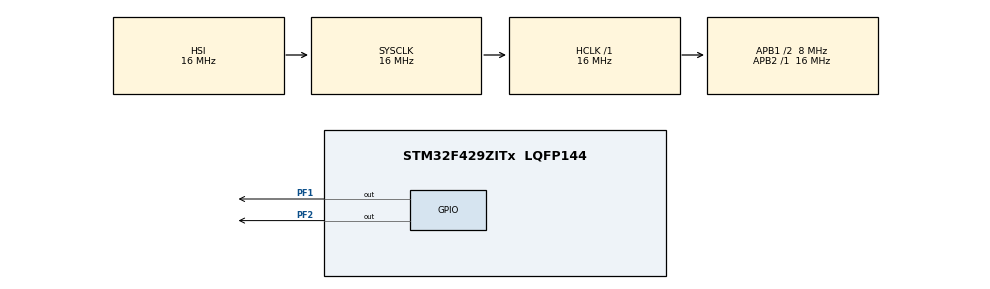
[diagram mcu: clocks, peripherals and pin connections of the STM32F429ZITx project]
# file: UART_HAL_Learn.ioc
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Mcu.Family=STM32F4
Mcu.Name=STM32F429ZITx
Mcu.Package=LQFP144
NVIC.PriorityGroup=NVIC_PRIORITYGROUP_4
PA13.Mode=Serial_Wire
PA13.Signal=SYS_JTMS-SWDIO
PA14.Mode=Serial_Wire
PA14.Signal=SYS_JTCK-SWCLK
PF1.Signal=GPIO_Output
PF2.Signal=GPIO_Output
ProjectManager.HeapSize=0x200
ProjectManager.StackSize=0x400
ProjectManager.TargetToolchain=STM32CubeIDE
RCC.48MHZClocksFreq_Value=96000000
RCC.AHBFreq_Value=16000000
RCC.APB1CLKDivider=RCC_HCLK_DIV2
RCC.APB1Freq_Value=8000000
RCC.APB1TimFreq_Value=16000000
RCC.APB2Freq_Value=16000000
RCC.APB2TimFreq_Value=16000000
RCC.CortexFreq_Value=16000000
RCC.HCLKFreq_Value=16000000
RCC.HSE_VALUE=8000000
RCC.HSI_VALUE=16000000
RCC.LSE_VALUE=32768
RCC.PLLM=4
RCC.PLLN=120
RCC.PLLQ=5
RCC.PLLSAIN=50
RCC.SYSCLKFreq_VALUE=16000000
RCC.VCOOutputFreq_Value=480000000
board=STM32F429I-DISC1

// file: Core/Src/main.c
/* USER CODE BEGIN Header */
/**
  ******************************************************************************
  * @file           : main.c
  * @brief          : Main program body
  ******************************************************************************
  * @attention
  *
  * Copyright (c) 2024 STMicroelectronics.
  * All rights reserved.
  *
  * This software is licensed under terms that can be found in the LICENSE file
  * in the root directory of this software component.
  * If no LICENSE file comes with this software, it is provided AS-IS.
  *
  ******************************************************************************
  */
/* USER CODE END Header */
#include "main.h"

void SystemClock_Config(void);
static void MX_GPIO_Init(void);

int main(void)
{

  /* MCU Configuration--------------------------------------------------------*/

  /* Reset of all peripherals, Initializes the Flash interface and the Systick. */
  HAL_Init();

  /* Configure the system clock */
  SystemClock_Config();

  /* Initialize all configured peripherals */
  MX_GPIO_Init();
  /* USER CODE BEGIN 2 */
  /** Enable clock access to GPIOA, USART1 */
  __HAL_RCC_USART1_CLK_ENABLE();
  /** Configure PA9, PA10 to Alternate function mode, value = 7 */
  GPIO_InitTypeDef GPIO_USART1;
  GPIO_USART1.Pin = GPIO_PIN_9 | GPIO_PIN_10;
  GPIO_USART1.Mode = GPIO_MODE_AF_PP;
  GPIO_USART1.Alternate = GPIO_AF7_USART1;
  HAL_GPIO_Init(GPIOA, &GPIO_USART1);
  /** Configure USART1 */
  UART_InitTypeDef UART1_Init;
  UART1_Init.OverSampling = UART_OVERSAMPLING_16;
  UART1_Init.Mode = UART_MODE_TX_RX;
  UART1_Init.WordLength = UART_WORDLENGTH_8B;
  UART1_Init.Parity = UART_PARITY_NONE;
  UART1_Init.StopBits = UART_STOPBITS_1;
  UART1_Init.BaudRate = 9600U;
  UART_HandleTypeDef hUART1;
  hUART1.Init = UART1_Init;
  hUART1.Instance = USART1;
  HAL_UART_Init(&hUART1);
//  __HAL_UART_ENABLE(&hUART1);

  /* USER CODE END 2 */

  /* Infinite loop */
  /* USER CODE BEGIN WHILE */
  unsigned char data = 0;
  const unsigned char carriage_return = '\r';
  const unsigned char line_feed = '\n';
  while (1)
  {
    /* USER CODE END WHILE */

    /* USER CODE BEGIN 3 */
	while(!__HAL_UART_GET_FLAG(&hUART1, UART_FLAG_RXNE)){}
	HAL_UART_Receive(&hUART1, &data, 1, 10000);
	while(!__HAL_UART_GET_FLAG(&hUART1,UART_FLAG_TXE)){}
	if(data != '\r')
		HAL_UART_Transmit(&hUART1, &data, 1, 10000);
	if(data == '\r'){
	while(!__HAL_UART_GET_FLAG(&hUART1,UART_FLAG_TXE)){}
	HAL_UART_Transmit(&hUART1, &carriage_return, 1, 10000);
	while(!__HAL_UART_GET_FLAG(&hUART1,UART_FLAG_TXE)){}
	HAL_UART_Transmit(&hUART1, &line_feed, 1, 10000);
	}

  }
  /* USER CODE END 3 */
}

void SystemClock_Config(void)
{
  RCC_OscInitTypeDef RCC_OscInitStruct = {0};
  RCC_ClkInitTypeDef RCC_ClkInitStruct = {0};

  /** Configure the main internal regulator output voltage
  */
  __HAL_RCC_PWR_CLK_ENABLE();
  __HAL_PWR_VOLTAGESCALING_CONFIG(PWR_REGULATOR_VOLTAGE_SCALE3);

  /** Initializes the RCC Oscillators according to the specified parameters
  * in the RCC_OscInitTypeDef structure.
  */
  RCC_OscInitStruct.OscillatorType = RCC_OSCILLATORTYPE_HSI;
  RCC_OscInitStruct.HSIState = RCC_HSI_ON;
  RCC_OscInitStruct.HSICalibrationValue = RCC_HSICALIBRATION_DEFAULT;
  RCC_OscInitStruct.PLL.PLLState = RCC_PLL_NONE;
  if (HAL_RCC_OscConfig(&RCC_OscInitStruct) != HAL_OK)
  {
    Error_Handler();
  }

  /** Initializes the CPU, AHB and APB buses clocks
  */
  RCC_ClkInitStruct.ClockType = RCC_CLOCKTYPE_HCLK|RCC_CLOCKTYPE_SYSCLK
                              |RCC_CLOCKTYPE_PCLK1|RCC_CLOCKTYPE_PCLK2;
  RCC_ClkInitStruct.SYSCLKSource = RCC_SYSCLKSOURCE_HSI;
  RCC_ClkInitStruct.AHBCLKDivider = RCC_SYSCLK_DIV1;
  RCC_ClkInitStruct.APB1CLKDivider = RCC_HCLK_DIV2;
  RCC_ClkInitStruct.APB2CLKDivider = RCC_HCLK_DIV1;

  if (HAL_RCC_ClockConfig(&RCC_ClkInitStruct, FLASH_LATENCY_0) != HAL_OK)
  {
    Error_Handler();
  }
}

static void MX_GPIO_Init(void)
{
  GPIO_InitTypeDef GPIO_InitStruct = {0};

  /* GPIO Ports Clock Enable */
  __HAL_RCC_GPIOF_CLK_ENABLE();
  __HAL_RCC_GPIOA_CLK_ENABLE();

  /*Configure GPIO pin Output Level */
  HAL_GPIO_WritePin(GPIOF, GPIO_PIN_1|GPIO_PIN_2, GPIO_PIN_RESET);

  /*Configure GPIO pins : PF1 PF2 */
  GPIO_InitStruct.Pin = GPIO_PIN_1|GPIO_PIN_2;
  GPIO_InitStruct.Mode = GPIO_MODE_OUTPUT_PP;
  GPIO_InitStruct.Pull = GPIO_NOPULL;
  GPIO_InitStruct.Speed = GPIO_SPEED_FREQ_LOW;
  HAL_GPIO_Init(GPIOF, &GPIO_InitStruct);

}

void Error_Handler(void)
{
  __disable_irq();
  while (1)
  {
  }
}
